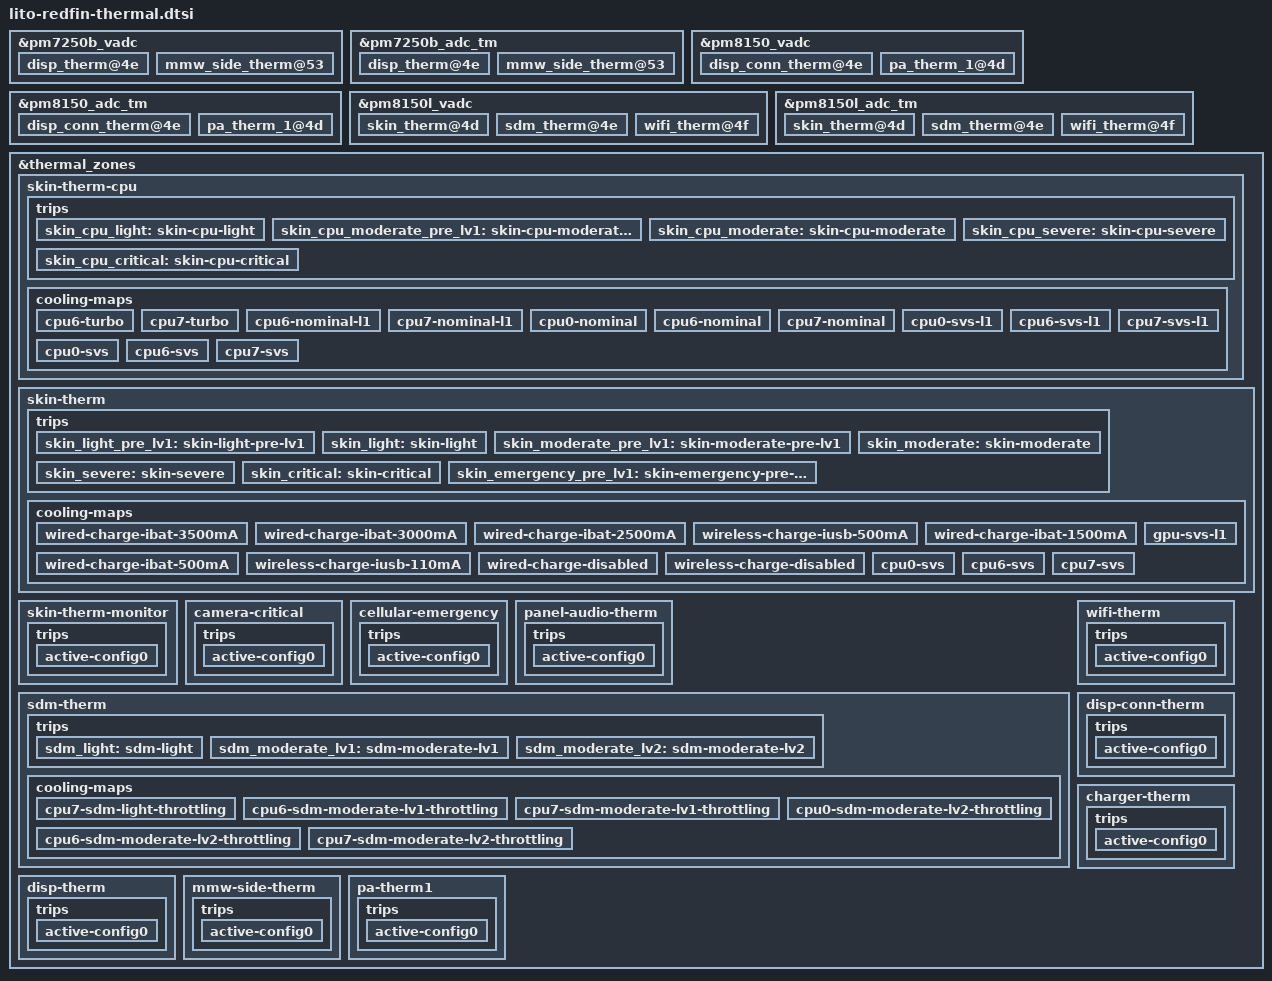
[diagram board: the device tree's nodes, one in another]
// SPDX-License-Identifier: GPL-2.0
/* Copyright (c) 2019, The Linux Foundation. All rights reserved.
 *
 * This program is free software; you can redistribute it and/or modify
 * it under the terms of the GNU General Public License version 2 and
 * only version 2 as published by the Free Software Foundation.
 *
 * This program is distributed in the hope that it will be useful,
 * but WITHOUT ANY WARRANTY; without even the implied warranty of
 * MERCHANTABILITY or FITNESS FOR A PARTICULAR PURPOSE.  See the
 * GNU General Public License for more details.
 */

&pm7250b_vadc {
	disp_therm@4e {
		reg = <ADC_AMUX_THM2_PU2>;
		label = "disp_therm";
		qcom,ratiometric;
		qcom,hw-settle-time = <200>;
		qcom,pre-scaling = <1 1>;
	};

	mmw_side_therm@53 {
		reg = <ADC_GPIO2_PU2>;
		label = "mmw_side_therm";
		qcom,ratiometric;
		qcom,hw-settle-time = <200>;
		qcom,pre-scaling = <1 1>;
	};
};

&pm7250b_adc_tm {
	io-channels = <&pm7250b_vadc ADC_AMUX_THM1_PU2>,
			<&pm7250b_vadc ADC_AMUX_THM2_PU2>,
			<&pm7250b_vadc ADC_AMUX_THM3_PU2>,
			<&pm7250b_vadc ADC_GPIO2_PU2>;

	disp_therm@4e {
		reg = <ADC_AMUX_THM2_PU2>;
		qcom,ratiometric;
		qcom,hw-settle-time = <200>;
	};

	mmw_side_therm@53 {
		reg = <ADC_GPIO2_PU2>;
		qcom,ratiometric;
		qcom,hw-settle-time = <200>;
	};
};

&pm8150_vadc {

	disp_conn_therm@4e {
		reg = <ADC_AMUX_THM2_PU2>;
		label = "disp_conn_therm";
		qcom,ratiometric;
		qcom,hw-settle-time = <200>;
		qcom,pre-scaling = <1 1>;
	};

	pa_therm_1@4d {
		reg = <ADC_AMUX_THM1_PU2>;
		label = "pa_therm_1";
		qcom,ratiometric;
		qcom,hw-settle-time = <200>;
		qcom,pre-scaling = <1 1>;
	};
};

&pm8150_adc_tm {
	io-channels = <&pm8150_vadc ADC_XO_THERM_PU2>,
			<&pm8150_vadc ADC_AMUX_THM1_PU2>,
			<&pm8150_vadc ADC_AMUX_THM2_PU2>;

	disp_conn_therm@4e {
		reg = <ADC_AMUX_THM2_PU2>;
		qcom,ratiometric;
		qcom,hw-settle-time = <200>;
	};

	pa_therm_1@4d {
		reg = <ADC_AMUX_THM1_PU2>;
		qcom,ratiometric;
		qcom,hw-settle-time = <200>;
	};
};

&pm8150l_vadc {
	skin_therm@4d {
		reg = <ADC_AMUX_THM1_PU2>;
		label = "skin_therm";
		qcom,ratiometric;
		qcom,hw-settle-time = <200>;
		qcom,pre-scaling = <1 1>;
	};

	sdm_therm@4e {
		reg = <ADC_AMUX_THM2_PU2>;
		label = "sdm_therm";
		qcom,ratiometric;
		qcom,hw-settle-time = <200>;
		qcom,pre-scaling = <1 1>;
	};

	wifi_therm@4f {
		reg = <ADC_AMUX_THM3_PU2>;
		label = "wifi_therm";
		qcom,ratiometric;
		qcom,hw-settle-time = <200>;
		qcom,pre-scaling = <1 1>;
	};
};

&pm8150l_adc_tm {
	io-channels = <&pm8150l_vadc ADC_AMUX_THM1_PU2>,
			<&pm8150l_vadc ADC_AMUX_THM2_PU2>,
			<&pm8150l_vadc ADC_AMUX_THM3_PU2>;

	/* Channel nodes */
	skin_therm@4d {
		reg = <ADC_AMUX_THM1_PU2>;
		qcom,ratiometric;
		qcom,hw-settle-time = <200>;
	};

	sdm_therm@4e {
		reg = <ADC_AMUX_THM2_PU2>;
		qcom,ratiometric;
		qcom,hw-settle-time = <200>;
	};

	wifi_therm@4f {
		reg = <ADC_AMUX_THM3_PU2>;
		qcom,ratiometric;
		qcom,hw-settle-time = <200>;
	};
};

&thermal_zones {
	skin-therm-cpu {
		polling-delay-passive = <5000>;
		polling-delay = <0>;
		thermal-governor = "step_wise";
		thermal-sensors = <&pm8150l_adc_tm ADC_AMUX_THM1_PU2>;
		wake-capable-sensor;
		trips {
			skin_cpu_light: skin-cpu-light {
				temperature = <37000>;
				hysteresis = <1000>;
				type = "passive";
			};
			skin_cpu_moderate_pre_lv1: skin-cpu-moderate-pre-lv1 {
				temperature = <39000>;
				hysteresis = <1000>;
				type = "passive";
			};
			skin_cpu_moderate: skin-cpu-moderate {
				temperature = <41000>;
				hysteresis = <1000>;
				type = "passive";
			};
			skin_cpu_severe: skin-cpu-severe {
				temperature = <43000>;
				hysteresis = <1000>;
				type = "passive";
			};
			skin_cpu_critical: skin-cpu-critical {
				temperature = <45000>;
				hysteresis = <1000>;
				type = "passive";
			};
		};
		cooling-maps {
			/* light throttling */
			cpu6-turbo {
				trip = <&skin_cpu_light>;
				cooling-device =
					<&CPU6 1 2>;
			};
			cpu7-turbo {
				trip = <&skin_cpu_light>;
				cooling-device =
					<&CPU7 1 1>;
			};
			/* moderate pre level 1 throttling */
			cpu6-nominal-l1 {
				trip = <&skin_cpu_moderate_pre_lv1>;
				cooling-device =
					<&CPU6 3 3>;
			};
			cpu7-nominal-l1 {
				trip = <&skin_cpu_moderate_pre_lv1>;
				cooling-device =
					<&CPU7 2 3>;
			};
			/* moderate throttling */
			cpu0-nominal {
				trip = <&skin_cpu_moderate>;
				cooling-device =
					<&CPU0 1 3>;
			};
			cpu6-nominal {
				trip = <&skin_cpu_moderate>;
				cooling-device =
					<&CPU6 4 4>;
			};
			cpu7-nominal {
				trip = <&skin_cpu_moderate>;
				cooling-device =
					<&CPU7 4 4>;
			};
			/* severe throttling */
			cpu0-svs-l1 {
				trip = <&skin_cpu_severe>;
				cooling-device =
					<&CPU0 4 4>;
			};
			cpu6-svs-l1 {
				trip = <&skin_cpu_severe>;
				cooling-device =
					<&CPU6 5 5>;
			};
			cpu7-svs-l1 {
				trip = <&skin_cpu_severe>;
				cooling-device =
					<&CPU7 5 5>;
			};
			/* critical throttling */
			cpu0-svs {
				trip = <&skin_cpu_critical>;
				cooling-device =
					<&CPU0 5 5>;
			};
			cpu6-svs {
				trip = <&skin_cpu_critical>;
				cooling-device =
					<&CPU6 6 6>;
			};
			cpu7-svs {
				trip = <&skin_cpu_critical>;
				cooling-device =
					<&CPU7 6 6>;
			};
		};
	};

	skin-therm {
		polling-delay-passive = <5000>;
		polling-delay = <0>;
		thermal-governor = "step_wise";
		thermal-sensors = <&pm8150l_adc_tm ADC_AMUX_THM1_PU2>;
		wake-capable-sensor;
		trips {
			skin_light_pre_lv1: skin-light-pre-lv1 {
				temperature = <36000>;
				hysteresis = <1000>;
				type = "passive";
			};
			skin_light: skin-light {
				temperature = <37000>;
				hysteresis = <1000>;
				type = "passive";
			};
			skin_moderate_pre_lv1: skin-moderate-pre-lv1 {
				temperature = <39000>;
				hysteresis = <1000>;
				type = "passive";
			};
			skin_moderate: skin-moderate {
				temperature = <41000>;
				hysteresis = <1000>;
				type = "passive";
			};
			skin_severe: skin-severe {
				temperature = <43000>;
				hysteresis = <1000>;
				type = "passive";
			};
			skin_critical: skin-critical {
				temperature = <45000>;
				hysteresis = <1000>;
				type = "passive";
			};
			skin_emergency_pre_lv1: skin-emergency-pre-lv1 {
				temperature = <48000>;
				hysteresis = <1000>;
				type = "passive";
			};
		};
		cooling-maps {
			/* light pre level 1 throttling */
			wired-charge-ibat-3500mA {
				trip = <&skin_light_pre_lv1>;
				cooling-device =
					<&google_charger 1 1>;
			};
			/* light throttling */
			wired-charge-ibat-3000mA {
				trip = <&skin_light>;
				cooling-device =
					<&google_charger 2 2>;
			};
			/* moderate pre level 1 throttling */
			wired-charge-ibat-2500mA {
				trip = <&skin_moderate_pre_lv1>;
				cooling-device =
					<&google_charger 3 3>;
			};
			wireless-charge-iusb-500mA {
				trip = <&skin_moderate_pre_lv1>;
				cooling-device =
					<&google_wlc_charger 1 1>;
			};
			/* moderate throttling */
			wired-charge-ibat-1500mA {
				trip = <&skin_moderate>;
				cooling-device =
					<&google_charger 5 5>;
			};
			/* severe throttling */
			wired-charge-ibat-500mA {
				trip = <&skin_severe>;
				cooling-device =
					<&google_charger 7 7>;
			};
			wireless-charge-iusb-110mA {
				trip = <&skin_severe>;
				cooling-device =
					<&google_wlc_charger 2 2>;
			};
			/* critical throttling */
			wired-charge-disabled {
				trip = <&skin_critical>;
				cooling-device = <&google_charger
					THERMAL_MAX_LIMIT THERMAL_MAX_LIMIT>;
			};
			wireless-charge-disabled {
				trip = <&skin_critical>;
				cooling-device = <&google_wlc_charger
					THERMAL_MAX_LIMIT THERMAL_MAX_LIMIT>;
			};
			gpu-svs-l1 {
				trip = <&skin_critical>;
				cooling-device =
					<&msm_gpu 1 1>;
			};
			/* emergency pre level1 throttling */
			cpu0-svs {
				trip = <&skin_emergency_pre_lv1>;
				cooling-device =
					<&CPU0 5 5>;
			};
			cpu6-svs {
				trip = <&skin_emergency_pre_lv1>;
				cooling-device =
					<&CPU6 6 6>;
			};
			cpu7-svs {
				trip = <&skin_emergency_pre_lv1>;
				cooling-device =
					<&CPU7 6 6>;
			};
		};
	};

	skin-therm-monitor {
		polling-delay-passive = <0>;
		polling-delay = <0>;
		thermal-governor = "user_space";
		thermal-sensors = <&pm8150l_adc_tm ADC_AMUX_THM1_PU2>;
		wake-capable-sensor;
		trips {
			active-config0 {
				temperature = <125000>;
				hysteresis = <1000>;
				type = "passive";
			};
		};
	};

	camera-critical {
		polling-delay-passive = <0>;
		polling-delay = <0>;
		thermal-governor = "user_space";
		thermal-sensors = <&pm8150l_adc_tm ADC_AMUX_THM1_PU2>;
		wake-capable-sensor;
		trips {
			active-config0 {
				temperature = <125000>;
				hysteresis = <1000>;
				type = "passive";
			};
		};
	};

	cellular-emergency {
		polling-delay-passive = <0>;
		polling-delay = <0>;
		thermal-governor = "user_space";
		thermal-sensors = <&pm8150l_adc_tm ADC_AMUX_THM1_PU2>;
		wake-capable-sensor;
		trips {
			active-config0 {
				temperature = <125000>;
				hysteresis = <1000>;
				type = "passive";
			};
		};
	};

	panel-audio-therm {
		polling-delay-passive = <0>;
		polling-delay = <0>;
		thermal-governor = "user_space";
		thermal-sensors = <&pm8150l_adc_tm ADC_AMUX_THM1_PU2>;
		wake-capable-sensor;
		trips {
			active-config0 {
				temperature = <125000>;
				hysteresis = <1000>;
				type = "passive";
			};
		};
	};

	sdm-therm {
		polling-delay-passive = <2000>;
		polling-delay = <0>;
		thermal-governor = "step_wise";
		thermal-sensors = <&pm8150l_adc_tm ADC_AMUX_THM2_PU2>;
		wake-capable-sensor;
		trips {
			sdm_light: sdm-light {
				temperature = <63000>;
				hysteresis = <2000>;
				type = "passive";
			};
			sdm_moderate_lv1: sdm-moderate-lv1 {
				temperature = <65000>;
				hysteresis = <2000>;
				type = "passive";
			};
			sdm_moderate_lv2: sdm-moderate-lv2 {
				temperature = <67000>;
				hysteresis = <2000>;
				type = "passive";
			};
		};
		cooling-maps {
			/* sdm light throttling */
			cpu7-sdm-light-throttling {
				trip = <&sdm_light>;
				cooling-device =
				<&CPU7 1 1>;
			};
			/* sdm moderate throttling level 1 */
			cpu6-sdm-moderate-lv1-throttling {
				trip = <&sdm_moderate_lv1>;
				cooling-device =
				<&CPU6 1 2>;
			};
			cpu7-sdm-moderate-lv1-throttling {
				trip = <&sdm_moderate_lv1>;
				cooling-device =
				<&CPU7 2 4>;
			};
			/* sdm moderate throttling level 2 */
			cpu0-sdm-moderate-lv2-throttling {
				trip = <&sdm_moderate_lv2>;
				cooling-device =
				<&CPU0 1 2>;
			};
			cpu6-sdm-moderate-lv2-throttling {
				trip = <&sdm_moderate_lv2>;
				cooling-device =
				<&CPU6 2 3>;
			};
			cpu7-sdm-moderate-lv2-throttling {
				trip = <&sdm_moderate_lv2>;
				cooling-device =
				<&CPU7 4 5>;
			};
		};
	};

	wifi-therm {
		polling-delay-passive = <0>;
		polling-delay = <0>;
		thermal-governor = "user_space";
		thermal-sensors = <&pm8150l_adc_tm ADC_AMUX_THM3_PU2>;
		wake-capable-sensor;
		trips {
			active-config0 {
				temperature = <125000>;
				hysteresis = <1000>;
				type = "passive";
			};
		};
	};

	disp-conn-therm {
		polling-delay-passive = <0>;
		polling-delay = <0>;
		thermal-governor = "user_space";
		thermal-sensors = <&pm8150_adc_tm ADC_AMUX_THM2_PU2>;
		wake-capable-sensor;
		trips {
			active-config0 {
				temperature = <125000>;
				hysteresis = <1000>;
				type = "passive";
			};
		};
	};

	charger-therm {
		polling-delay-passive = <0>;
		polling-delay = <0>;
		thermal-governor = "user_space";
		thermal-sensors = <&pm7250b_adc_tm ADC_AMUX_THM1_PU2>;
		wake-capable-sensor;
		trips {
			active-config0 {
				temperature = <125000>;
				hysteresis = <1000>;
				type = "passive";
			};
		};
	};

	disp-therm {
		polling-delay-passive = <0>;
		polling-delay = <0>;
		thermal-governor = "user_space";
		thermal-sensors = <&pm7250b_adc_tm ADC_AMUX_THM2_PU2>;
		wake-capable-sensor;
		trips {
			active-config0 {
				temperature = <125000>;
				hysteresis = <1000>;
				type = "passive";
			};
		};
	};

	mmw-side-therm {
		polling-delay-passive = <0>;
		polling-delay = <0>;
		thermal-governor = "user_space";
		thermal-sensors = <&pm7250b_adc_tm ADC_GPIO2_PU2>;
		wake-capable-sensor;
		trips {
			active-config0 {
				temperature = <125000>;
				hysteresis = <1000>;
				type = "passive";
			};
		};
	};

	pa-therm1 {
		polling-delay-passive = <0>;
		polling-delay = <0>;
		thermal-governor = "user_space";
		thermal-sensors = <&pm8150_adc_tm ADC_AMUX_THM1_PU2>;
		wake-capable-sensor;
		trips {
			active-config0 {
				temperature = <125000>;
				hysteresis = <1000>;
				type = "passive";
			};
		};
	};
};
